VERSION ""

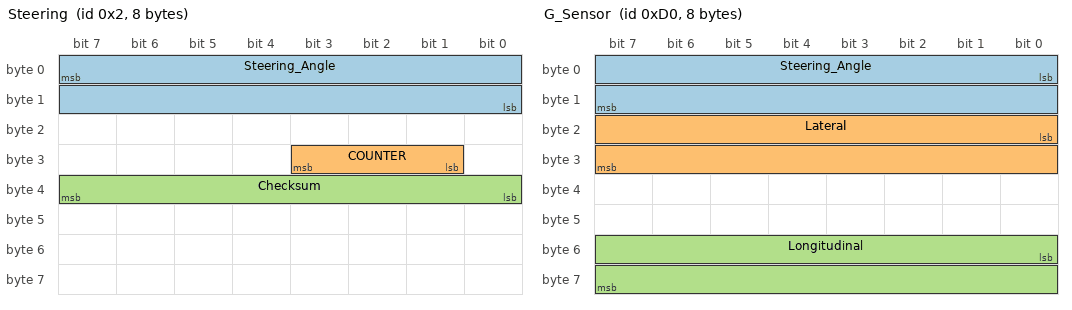
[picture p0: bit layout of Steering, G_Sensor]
BO_ 2 Steering: 8 XXX
 SG_ Steering_Angle : 7|16@0- (0.1,0) [-500|500] "degree" XXX
 SG_ COUNTER : 27|3@0+ (1,0) [0|7] "" XXX
 SG_ Checksum : 39|8@0+ (1,0) [0|255] "" XXX

BO_ 208 G_Sensor: 8 XXX
 SG_ Steering_Angle : 0|16@1- (-0.1,0) [-500|500] "" XXX
 SG_ Lateral : 16|16@1- (-0.0035,1) [-255|255] "" XXX
 SG_ Longitudinal : 48|16@1- (-0.00035,0) [-255|255] "" XXX

BO_ 209 Brake_Pedal: 8 XXX
 SG_ Speed : 0|16@1+ (0.05625,0) [0|255] "KPH" XXX
 SG_ Brake_Pedal : 16|8@1+ (1,0) [0|255] "" XXX

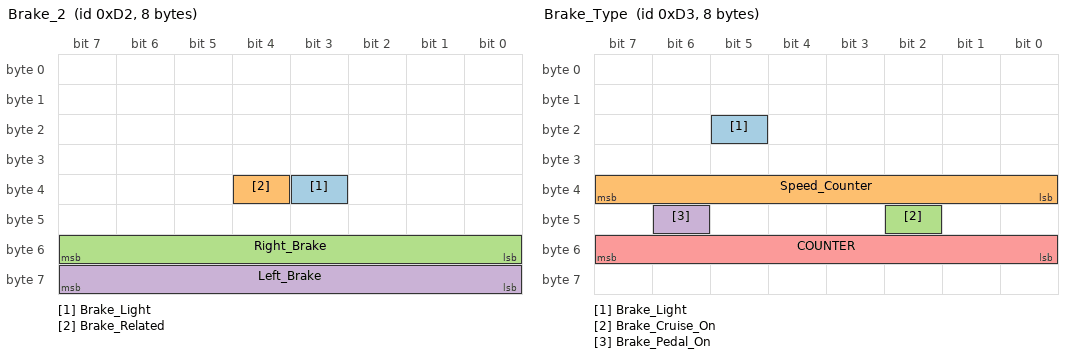
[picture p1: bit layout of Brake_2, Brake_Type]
BO_ 210 Brake_2: 8 XXX
 SG_ Brake_Light : 35|1@1+ (1,0) [0|1] "" XXX
 SG_ Brake_Related : 36|1@1+ (1,0) [0|1] "" XXX
 SG_ Right_Brake : 48|8@1+ (1,0) [0|255] "" XXX
 SG_ Left_Brake : 56|8@1+ (1,0) [0|255] "" XXX

BO_ 211 Brake_Type: 8 XXX
 SG_ Brake_Light : 21|1@1+ (1,0) [0|1] "" XXX
 SG_ Speed_Counter : 32|8@1+ (1,0) [0|255] "" XXX
 SG_ Brake_Cruise_On : 42|1@1+ (1,0) [0|1] "" XXX
 SG_ Brake_Pedal_On : 46|1@1+ (1,0) [0|1] "" XXX
 SG_ COUNTER : 48|8@1+ (1,0) [0|255] "" XXX

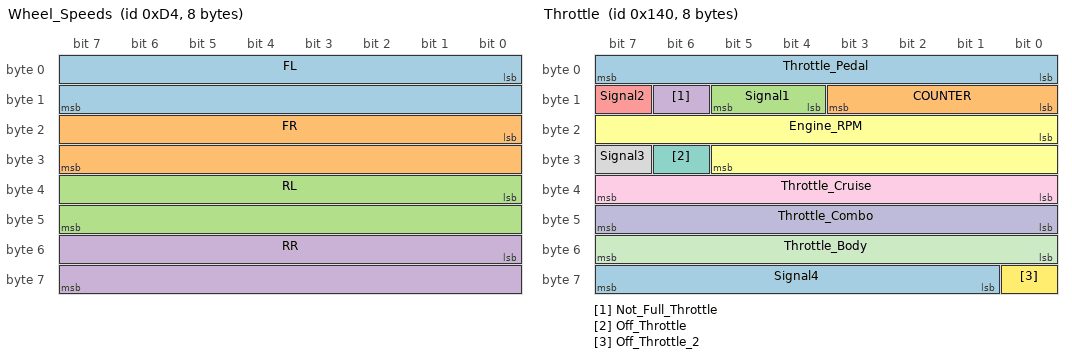
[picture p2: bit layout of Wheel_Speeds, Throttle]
BO_ 212 Wheel_Speeds: 8 XXX
 SG_ FL : 0|16@1+ (0.0592,0) [0|255] "KPH" XXX
 SG_ FR : 16|16@1+ (0.0592,0) [0|255] "KPH" XXX
 SG_ RL : 32|16@1+ (0.0592,0) [0|255] "KPH" XXX
 SG_ RR : 48|16@1+ (0.0592,0) [0|255] "KPH" XXX

BO_ 320 Throttle: 8 XXX
 SG_ Throttle_Pedal : 0|8@1+ (0.392157,0) [0|255] "" XXX
 SG_ COUNTER : 8|4@1+ (1,0) [0|15] "" XXX
 SG_ Signal1 : 12|2@1+ (1,0) [0|7] "" XXX
 SG_ Not_Full_Throttle : 14|1@1+ (1,0) [0|1] "" XXX
 SG_ Signal2 : 15|1@1+ (1,0) [0|1] "" XXX
 SG_ Engine_RPM : 16|14@1+ (1,0) [0|32767] "" XXX
 SG_ Off_Throttle : 30|1@1+ (1,0) [0|1] "" XXX
 SG_ Signal3 : 31|1@1+ (1,0) [0|1] "" XXX
 SG_ Throttle_Cruise : 32|8@1+ (1,0) [0|255] "" XXX
 SG_ Throttle_Combo : 40|8@1+ (1,0) [0|255] "" XXX
 SG_ Throttle_Body : 48|8@1+ (1,0) [0|255] "" XXX
 SG_ Off_Throttle_2 : 56|1@1+ (1,0) [0|1] "" XXX
 SG_ Signal4 : 57|7@1+ (1,0) [0|127] "" XXX

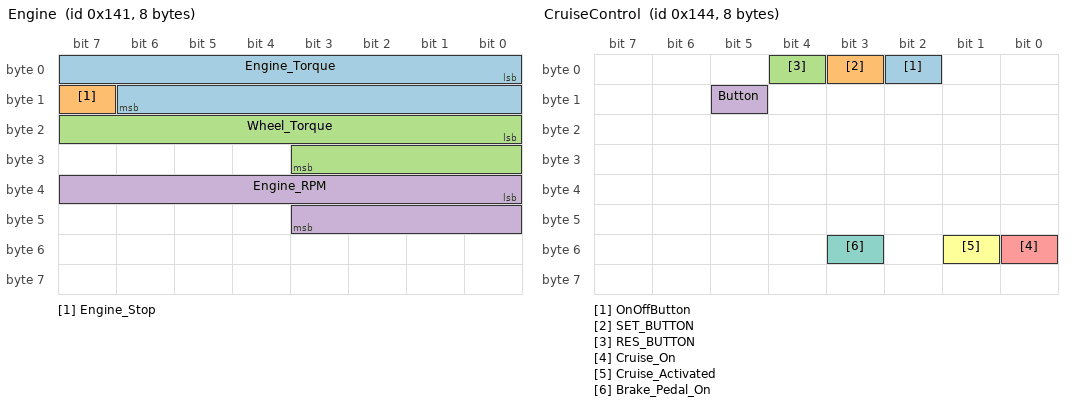
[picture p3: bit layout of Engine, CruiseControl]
BO_ 321 Engine: 8 XXX
 SG_ Engine_Torque : 0|15@1+ (1,0) [0|255] "" XXX
 SG_ Engine_Stop : 15|1@1+ (1,0) [0|1] "" XXX
 SG_ Wheel_Torque : 16|12@1+ (1,0) [0|4095] "" XXX
 SG_ Engine_RPM : 32|12@1+ (1,0) [0|8191] "" XXX

BO_ 324 CruiseControl: 8 XXX
 SG_ OnOffButton : 2|1@1+ (1,0) [0|1] "" XXX
 SG_ SET_BUTTON : 3|1@1+ (1,0) [0|1] "" XXX
 SG_ RES_BUTTON : 4|1@1+ (1,0) [0|1] "" XXX
 SG_ Button : 13|1@1+ (1,0) [0|1] "" XXX
 SG_ Cruise_On : 48|1@1+ (1,0) [0|1] "" XXX
 SG_ Cruise_Activated : 49|1@1+ (1,0) [0|1] "" XXX
 SG_ Brake_Pedal_On : 51|1@1+ (1,0) [0|1] "" XXX

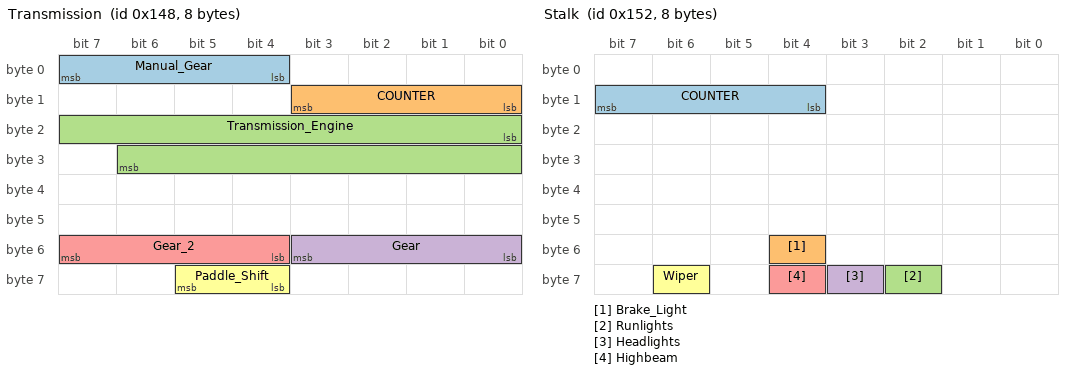
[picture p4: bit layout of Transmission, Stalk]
BO_ 328 Transmission: 8 XXX
 SG_ Manual_Gear : 4|4@1+ (1,0) [0|15] "" XXX
 SG_ COUNTER : 8|4@1+ (1,0) [0|15] "" XXX
 SG_ Transmission_Engine : 16|15@1+ (1,0) [0|65535] "" XXX
 SG_ Gear : 48|4@1+ (1,0) [0|15] "" XXX
 SG_ Gear_2 : 52|4@1+ (1,0) [0|15] "" XXX
 SG_ Paddle_Shift : 60|2@1+ (1,0) [0|3] "" XXX

BO_ 329 CVT_Ratio: 8 XXX

BO_ 336 Brake_Pressure: 8 XXX
 SG_ Brake_Pressure_Right : 0|8@1+ (1,0) [0|255] "" XXX
 SG_ Brake_Pressure_Left : 8|8@1+ (1,0) [0|255] "" XXX

BO_ 338 Stalk: 8 XXX
 SG_ COUNTER : 12|4@1+ (1,0) [0|15] "" XXX
 SG_ Brake_Light : 52|1@1+ (1,0) [0|1] "" XXX
 SG_ Runlights : 58|1@1+ (1,0) [0|1] "" XXX
 SG_ Headlights : 59|1@1+ (1,0) [0|1] "" XXX
 SG_ Highbeam : 60|1@1+ (1,0) [0|1] "" XXX
 SG_ Wiper : 62|1@1+ (1,0) [0|1] "" XXX

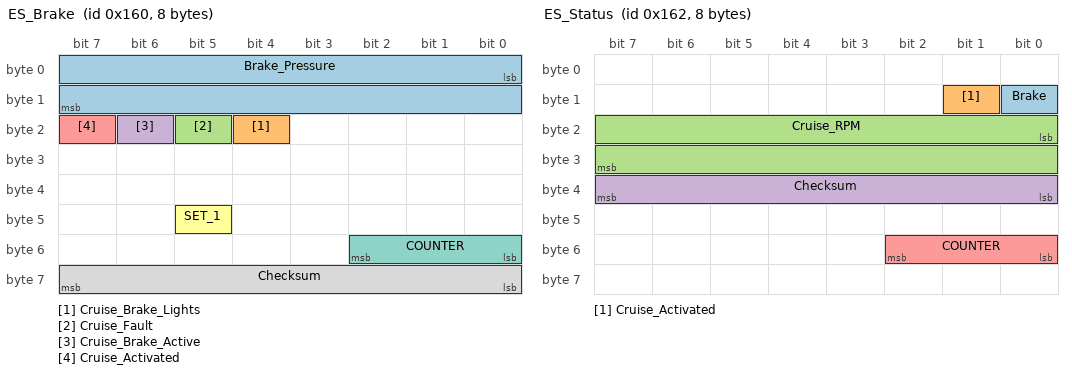
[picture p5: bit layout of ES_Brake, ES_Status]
BO_ 352 ES_Brake: 8 XXX
 SG_ Brake_Pressure : 0|16@1+ (1,0) [0|255] "" XXX
 SG_ Cruise_Brake_Lights : 20|1@1+ (1,0) [0|1] "" XXX
 SG_ Cruise_Fault : 21|1@1+ (1,0) [0|1] "" XXX
 SG_ Cruise_Brake_Active : 22|1@1+ (1,0) [0|1] "" XXX
 SG_ Cruise_Activated : 23|1@1+ (1,0) [0|1] "" XXX
 SG_ SET_1 : 45|1@0+ (1,0) [0|1] "" XXX
 SG_ COUNTER : 48|3@1+ (1,0) [0|7] "" XXX
 SG_ Checksum : 56|8@1+ (1,0) [0|255] "" XXX

BO_ 353 ES_Distance: 8 XXX
 SG_ Cruise_Throttle : 0|12@1+ (1,0) [0|4095] "" XXX
 SG_ Signal1 : 12|4@1+ (1,0) [0|15] "" XXX
 SG_ Car_Follow : 16|1@1+ (1,0) [0|1] "" XXX
 SG_ Signal2 : 17|3@1+ (1,0) [0|7] "" XXX
 SG_ Cruise_Brake_Active : 20|1@1+ (1,0) [0|1] "" XXX
 SG_ Distance_Swap : 21|1@1+ (1,0) [0|1] "" XXX
 SG_ Standstill : 22|1@1+ (1,0) [0|1] "" XXX
 SG_ Signal3 : 23|1@1+ (1,0) [0|1] "" XXX
 SG_ Close_Distance : 24|8@1+ (0.019607,0) [0|5] "m" XXX
 SG_ Signal4 : 32|9@1+ (1,0) [0|255] "" XXX
 SG_ Standstill_2 : 41|1@1+ (1,0) [0|1] "" XXX
 SG_ Cruise_Fault : 42|1@1+ (1,0) [0|1] "" XXX
 SG_ Signal5 : 43|1@1+ (1,0) [0|1] "" XXX
 SG_ COUNTER : 44|3@1+ (1,0) [0|7] "" XXX
 SG_ Signal6 : 47|1@1+ (1,0) [0|1] "" XXX
 SG_ Cruise_Button : 48|3@1+ (1,0) [0|7] "" XXX
 SG_ Signal7 : 51|5@1+ (1,0) [0|31] "" XXX
 SG_ Checksum : 56|8@1+ (1,0) [0|255] "" XXX

BO_ 354 ES_Status: 8 XXX
 SG_ Brake : 8|1@1+ (1,0) [0|1] "" XXX
 SG_ Cruise_Activated : 9|1@1+ (1,0) [0|1] "" XXX
 SG_ Cruise_RPM : 16|16@1+ (1,0) [0|65535] "" XXX
 SG_ Checksum : 32|8@1+ (1,0) [0|255] "" XXX
 SG_ COUNTER : 48|3@1+ (1,0) [0|7] "" XXX

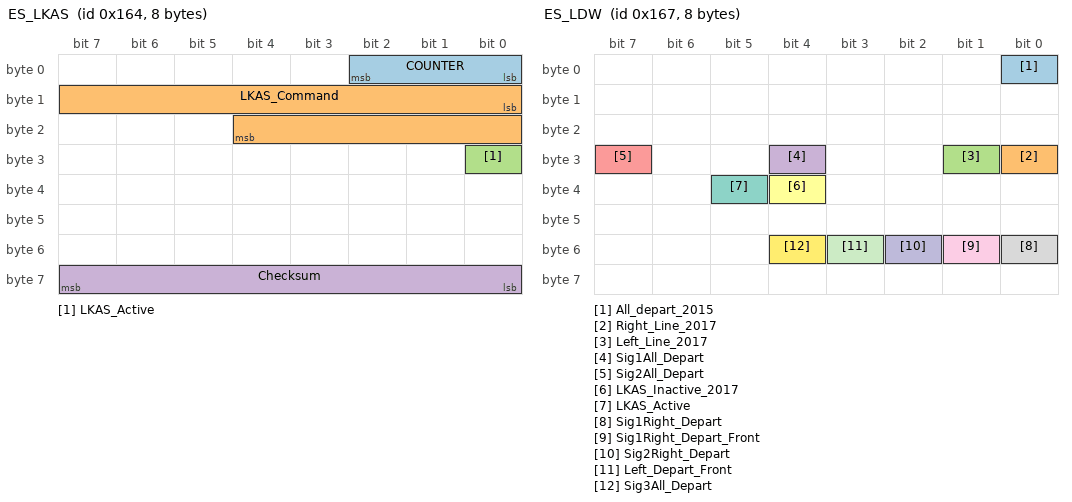
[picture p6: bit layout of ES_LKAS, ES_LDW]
BO_ 356 ES_LKAS: 8 XXX
 SG_ COUNTER : 0|3@1+ (1,0) [0|7] "" XXX
 SG_ LKAS_Command : 8|13@1- (-1,0) [-4096|4096] "" XXX
 SG_ LKAS_Active : 24|1@1+ (1,0) [0|1] "" XXX
 SG_ Checksum : 56|8@1+ (1,0) [0|255] "" XXX

BO_ 359 ES_LDW: 8 XXX
 SG_ All_depart_2015 : 0|1@1+ (1,0) [0|1] "" XXX
 SG_ Right_Line_2017 : 24|1@1+ (1,0) [0|1] "" XXX
 SG_ Left_Line_2017 : 25|1@1+ (1,0) [0|1] "" XXX
 SG_ Sig1All_Depart : 28|1@1+ (1,0) [0|1] "" XXX
 SG_ Sig2All_Depart : 31|1@1+ (1,0) [0|1] "" XXX
 SG_ LKAS_Inactive_2017 : 36|1@1+ (1,0) [0|1] "" XXX
 SG_ LKAS_Active : 37|1@1+ (1,0) [0|1] "" XXX
 SG_ Sig1Right_Depart : 48|1@1+ (1,0) [0|1] "" XXX
 SG_ Sig1Right_Depart_Front : 49|1@1+ (1,0) [0|1] "" XXX
 SG_ Sig2Right_Depart : 50|1@1+ (1,0) [0|1] "" XXX
 SG_ Left_Depart_Front : 51|1@1+ (1,0) [0|1] "" XXX
 SG_ Sig3All_Depart : 52|1@1+ (1,0) [0|1] "" XXX

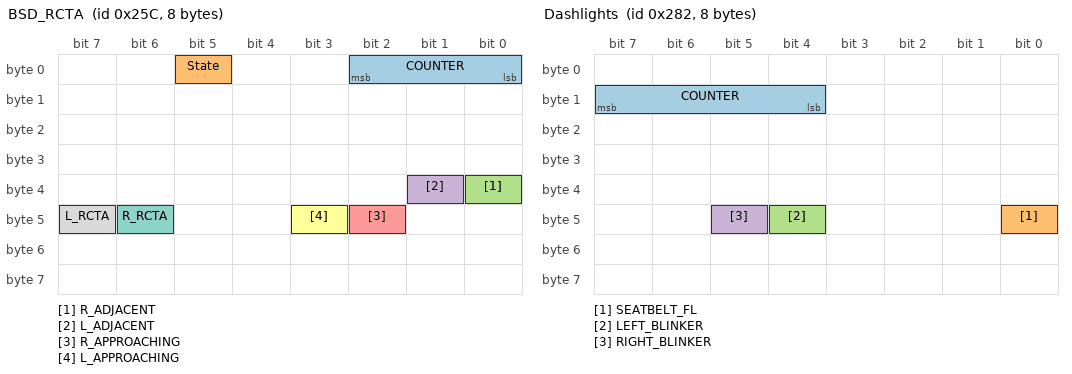
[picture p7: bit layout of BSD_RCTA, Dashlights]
BO_ 604 BSD_RCTA: 8 XXX
 SG_ COUNTER : 0|3@1+ (1,0) [0|7] "" XXX
 SG_ State : 5|1@1+ (1,0) [0|1] "" XXX
 SG_ R_ADJACENT : 32|1@1+ (1,0) [0|1] "" XXX
 SG_ L_ADJACENT : 33|1@1+ (1,0) [0|1] "" XXX
 SG_ R_APPROACHING : 42|1@1+ (1,0) [0|1] "" XXX
 SG_ L_APPROACHING : 43|1@1+ (1,0) [0|1] "" XXX
 SG_ R_RCTA : 46|1@1+ (1,0) [0|1] "" XXX
 SG_ L_RCTA : 47|1@1+ (1,0) [0|1] "" XXX

BO_ 642 Dashlights: 8 XXX
 SG_ COUNTER : 12|4@1+ (1,0) [0|15] "" XXX
 SG_ SEATBELT_FL : 40|1@1+ (1,0) [0|1] "" XXX
 SG_ LEFT_BLINKER : 44|1@1+ (1,0) [0|1] "" XXX
 SG_ RIGHT_BLINKER : 45|1@1+ (1,0) [0|1] "" XXX

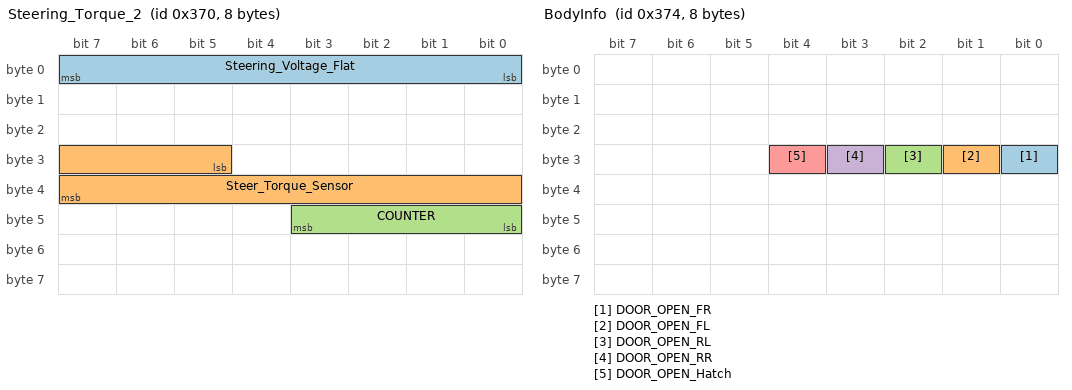
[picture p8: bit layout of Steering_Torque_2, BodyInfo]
BO_ 880 Steering_Torque_2: 8 XXX
 SG_ Steering_Voltage_Flat : 0|8@1+ (1,0) [0|255] "" XXX
 SG_ Steer_Torque_Sensor : 29|11@1- (-1,0) [-1000|1000] "" XXX
 SG_ COUNTER : 40|4@1+ (1,0) [0|15] "" XXX

BO_ 884 BodyInfo: 8 XXX
 SG_ DOOR_OPEN_FR : 24|1@1+ (1,0) [0|1] "" XXX
 SG_ DOOR_OPEN_FL : 25|1@1+ (1,0) [0|1] "" XXX
 SG_ DOOR_OPEN_RL : 26|1@1+ (1,0) [0|1] "" XXX
 SG_ DOOR_OPEN_RR : 27|1@1+ (1,0) [0|1] "" XXX
 SG_ DOOR_OPEN_Hatch : 28|1@1+ (1,0) [0|1] "" XXX

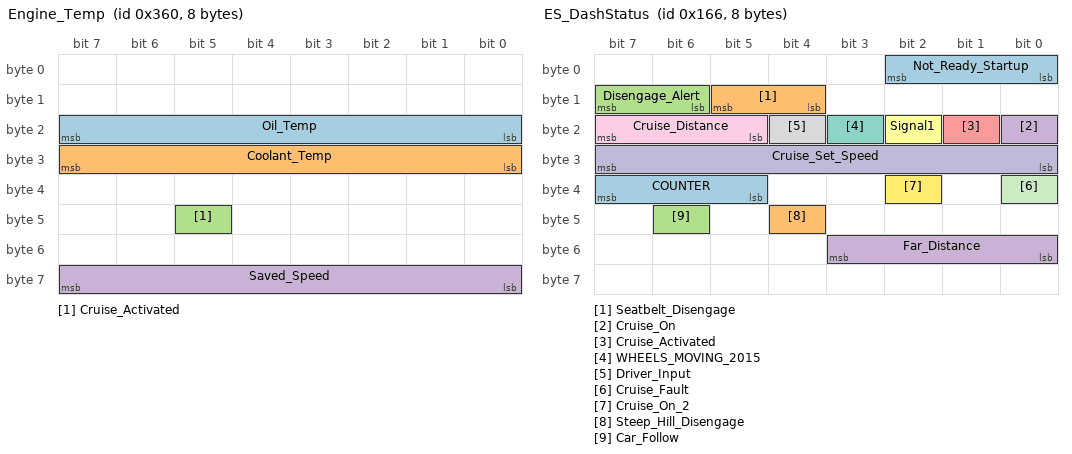
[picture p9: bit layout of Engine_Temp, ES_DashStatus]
BO_ 864 Engine_Temp: 8 XXX
 SG_ Oil_Temp : 16|8@1+ (1,-40) [0|255] "" XXX
 SG_ Coolant_Temp : 24|8@1+ (1,-40) [0|255] "" XXX
 SG_ Cruise_Activated : 45|1@1+ (1,0) [0|1] "" XXX
 SG_ Saved_Speed : 56|8@1+ (1,0) [0|255] "" XXX

BO_ 866 Fuel: 8 XXX

BO_ 977 Dash_State2: 8 XXX
 SG_ UNITS : 15|1@1+ (1,0) [0|1] "" XXX

BO_ 1745 Dash_State: 8 XXX
 SG_ Units : 15|1@1+ (1,0) [0|1] "" XXX

BO_ 358 ES_DashStatus: 8 XXX
 SG_ Not_Ready_Startup : 0|3@1+ (1,0) [0|7] "" XXX
 SG_ Seatbelt_Disengage : 12|2@1+ (1,0) [0|3] "" XXX
 SG_ Disengage_Alert : 14|2@1+ (1,0) [0|3] "" XXX
 SG_ Cruise_On : 16|1@1+ (1,0) [0|1] "" XXX
 SG_ Cruise_Activated : 17|1@1+ (1,0) [0|1] "" XXX
 SG_ Signal1 : 18|1@1+ (1,0) [0|1] "" XXX
 SG_ WHEELS_MOVING_2015 : 19|1@1+ (1,0) [0|1] "" XXX
 SG_ Driver_Input : 20|1@1+ (1,0) [0|1] "" XXX
 SG_ Cruise_Distance : 21|3@1+ (1,0) [0|7] "" XXX
 SG_ Cruise_Set_Speed : 24|8@1+ (1,0) [0|255] "" XXX
 SG_ Cruise_Fault : 32|1@1+ (1,0) [0|1] "" XXX
 SG_ Cruise_On_2 : 34|1@1+ (1,0) [0|1] "" XXX
 SG_ COUNTER : 37|3@1+ (1,0) [0|7] "" XXX
 SG_ Steep_Hill_Disengage : 44|1@1+ (1,0) [0|3] "" XXX
 SG_ Car_Follow : 46|1@1+ (1,0) [0|1] "" XXX
 SG_ Far_Distance : 48|4@1+ (5,0) [0|75] "m" XXX

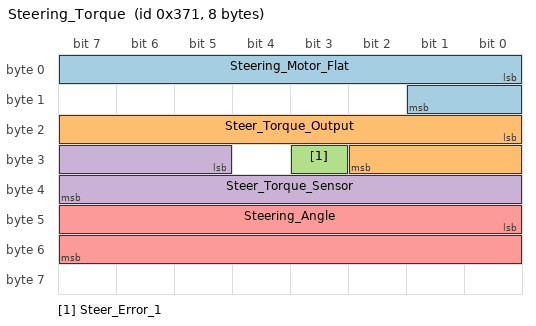
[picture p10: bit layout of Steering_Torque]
BO_ 881 Steering_Torque: 8 XXX
 SG_ Steering_Motor_Flat : 0|10@1+ (32,0) [0|1000] "" XXX
 SG_ Steer_Torque_Output : 16|11@1- (-32,0) [-1000|1000] "" XXX
 SG_ Steer_Error_1 : 27|1@1+ (1,0) [0|1] "" XXX
 SG_ Steer_Torque_Sensor : 29|11@1- (1,0) [-1000|1000] "" XXX
 SG_ Steering_Angle : 40|16@1- (-0.033,0) [-600|600] "" XXX

BU_: XXX

CM_ "AUTOGENERATED FILE, DO NOT EDIT";

CM_ "Imported file _subaru_global.dbc starts here";
CM_ SG_ 64 Throttle_Combo "Throttle Cruise + Pedal";
CM_ SG_ 313 Brake_Lights "Driver or Cruise Brake on";
CM_ SG_ 544 Cruise_Brake_Lights "1 = switch on brake lights";
CM_ SG_ 544 Brake_Pressure "Winds down after cruise disabled. Also can be non-zero when likely preparing for AEB";
CM_ SG_ 544 Signal3 "Usually goes to 2 if AEB_Status is 4";
CM_ SG_ 544 AEB_Status "Occasionally is 4 instead of 8 while Brake_Pressure is non-zero, unsure why";
CM_ SG_ 801 PCB_Off "Pre-Collision Braking off";
CM_ SG_ 801 Brake_Lights "Driver or Cruise brake on";
CM_ SG_ 801 Cruise_State "0 = Normal, 1 = Hold+User Brake, 2 = Ready, 3 = Hold";
CM_ SG_ 801 Far_Distance "1=0-5m, 2=5-10m, 3=10-15m, 4=15-20m, 5=20-25m, 6=25-30m, 7=30-35m, 8=35-40m, 9=40-45m, 10=45-50m, 11=50-55m, 12=55-60m, 13=60-65m, 14=65-70m, 15=75m+";
CM_ SG_ 801 LKAS_State_Msg "1 = LKAS_Off_Sharp_Curve, 2 = Keep_Hands_On_Steering_wheel_disabled, 3 = LKAS_Off, 4 = LKAS_Off_Too_Slow, 5 = LKAS_Off_Too_Fast";
CM_ SG_ 801 Cruise_State_Msg "1 = Cruise_Off_Steep_Slope, 2 = Cruise_lvl1_eco, 3 = Cruise_lvl2_comfort, 4 = Cruise_off_empty_reason, 5 = Cruise_off, 6 = Cruise_Unable_to_set, 7 = Cruise_Unable_to_set_brakes_applied, 8 = Eyesight_not_ready, 9 = Cruise_lvl3_standard, 10 = Cruise_lvl4_dynamic, 11 = Cruise_Unable_to_set_steep_slope";
CM_ SG_ 801 Cruise_Soft_Disable "Eyesight soft disable (eg direct sunlight)";
CM_ SG_ 801 Cruise_Status_Msg "1 = Disabled_Bad_Visibility, 2 = Disabled_Check_Manual";
CM_ SG_ 802 LKAS_ACTIVE "Turns on the full LKAS dash display";
CM_ SG_ 802 LKAS_Alert_Msg "1 = Keep_Hands_On_Wheel, 6 = Pre_Collision_Braking, 7 = Keep_Hands_On_Wheel_Off";
CM_ SG_ 802 LKAS_Alert "1 = FCW_Cont_Beep, 2 = FCW_Repeated_Beep, 3 = Throttle_Management_Activated_Warning, 4 = Throttle_Management_Activated_Alert, 5 = Pre_Collision_Activated_Alert, 8 = Traffic_Light_Ahead, 9 = Apply_Brake_to_Hold Position, 11 = LDW_Right, 12 = LDW_Left, 13 = Stay_Alert, 14 = Lead_Vehicle_Start_Alert, 18 = Keep_Hands_On_Steering_Alert, 24 = Audio_Beep, 25 = Audio_Lead_Car_Change, 26 = Audio_ACC_Disengaged, 27 = Audio_LKAS_disabled, 28 = Audio_Ding_Ding, 30 = Audio_Repeated_Beep";
CM_ SG_ 802 LKAS_Left_Line_Visible "0 = Off, 1 = White, 2 = Green, 3 = Orange";
CM_ SG_ 802 LKAS_Dash_State "0 = Off, 1 = Ready, 2 = Active";
CM_ SG_ 802 LKAS_Right_Line_Visible "0 = Off, 1 = White, 2 = Green, 3 = Orange";
CM_ SG_ 912 UNITS "0 = Metric, 1 = Imperial";
CM_ SG_ 912 ICY_ROAD "1 = DASHLIGHT ON, 2 = WARNING, 3 = OFF";
CM_ "subaru_global_2020_hybrid.dbc starts here";

VAL_ 992 CurrentGear 5 "1" 6 "2" 7 "3" 8 "4" ;
VAL_ 992 SelectorPosition 1 "P" 2 "R" 3 "N" 4 "D" 7 "3" 6 "2" 5 "1" ;
